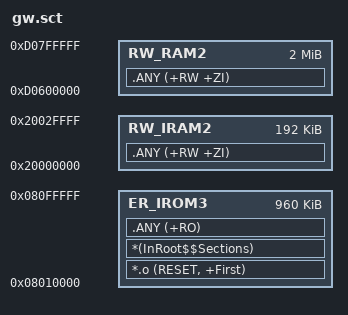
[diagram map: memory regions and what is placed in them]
; *************************************************************
; *** Scatter-Loading Description File generated by uVision ***
; *************************************************************
                  
LR_IROM3 0x08010000 0xF0000    		; load region size_region  
{
	ER_IROM3 0x08010000 0xF0000  	; load address = execution address  
	{
		*.o (RESET, +First)
		*(InRoot$$Sections)
		.ANY (+RO)
	}
    RW_IRAM2 0x20000000 0x00030000  
    {
        .ANY (+RW +ZI)
    }
	RW_RAM2	0xD0600000 0x00200000  	; SDRAM (2MB)
	{  
		.ANY (+RW +ZI)              ; GUI ram
	}
}

